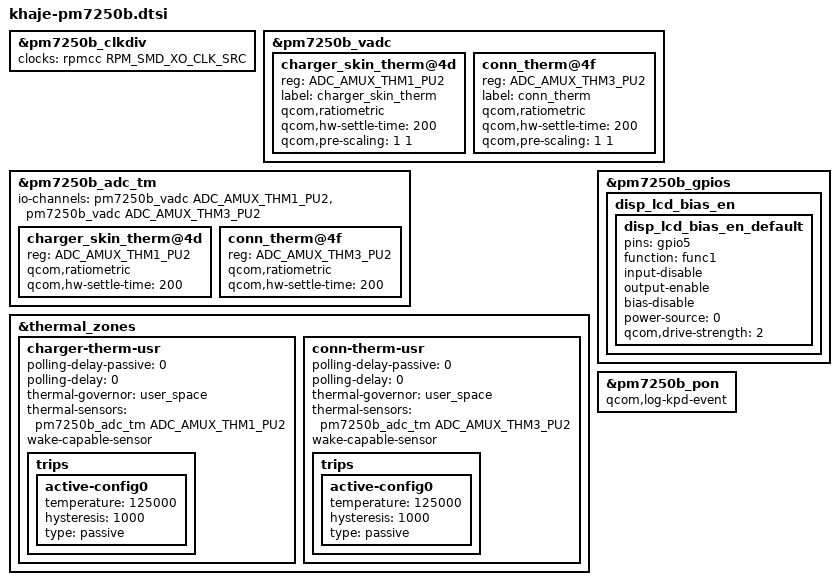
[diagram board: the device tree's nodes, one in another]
#include <dt-bindings/clock/qcom,rpmcc.h>
#include <dt-bindings/clock/qcom,rpmh.h>
#include "pm7250b.dtsi"

&pm7250b_clkdiv {
	clocks = <&rpmcc RPM_SMD_XO_CLK_SRC>;
};

&pm7250b_vadc {
	charger_skin_therm@4d {
		reg = <ADC_AMUX_THM1_PU2>;
		label = "charger_skin_therm";
		qcom,ratiometric;
		qcom,hw-settle-time = <200>;
		qcom,pre-scaling = <1 1>;
	};

	conn_therm@4f {
		reg = <ADC_AMUX_THM3_PU2>;
		label = "conn_therm";
		qcom,ratiometric;
		qcom,hw-settle-time = <200>;
		qcom,pre-scaling = <1 1>;
	};
};

&pm7250b_adc_tm {
	io-channels = <&pm7250b_vadc ADC_AMUX_THM1_PU2>,
			<&pm7250b_vadc ADC_AMUX_THM3_PU2>;

	/* Channel nodes */
	charger_skin_therm@4d {
		reg = <ADC_AMUX_THM1_PU2>;
		qcom,ratiometric;
		qcom,hw-settle-time = <200>;
	};

	conn_therm@4f {
		reg = <ADC_AMUX_THM3_PU2>;
		qcom,ratiometric;
		qcom,hw-settle-time = <200>;
	};
};

&thermal_zones {
	charger-therm-usr {
		polling-delay-passive = <0>;
		polling-delay = <0>;
		thermal-governor = "user_space";
		thermal-sensors = <&pm7250b_adc_tm ADC_AMUX_THM1_PU2>;
		wake-capable-sensor;
		trips {
			active-config0 {
				temperature = <125000>;
				hysteresis = <1000>;
				type = "passive";
			};
		};
	};

	conn-therm-usr {
		polling-delay-passive = <0>;
		polling-delay = <0>;
		thermal-governor = "user_space";
		thermal-sensors = <&pm7250b_adc_tm ADC_AMUX_THM3_PU2>;
		wake-capable-sensor;
		trips {
			active-config0 {
				temperature = <125000>;
				hysteresis = <1000>;
				type = "passive";
			};
		};
	};
};

&pm7250b_gpios {
	disp_lcd_bias_en {
		disp_lcd_bias_en_default: disp_lcd_bias_en_default {
			pins = "gpio5";
			function = "func1";
			input-disable;
			output-enable;
			bias-disable;
			power-source = <0>;
			qcom,drive-strength = <2>;
		};
	};
};

&pm7250b_pon {
	qcom,log-kpd-event;
};
